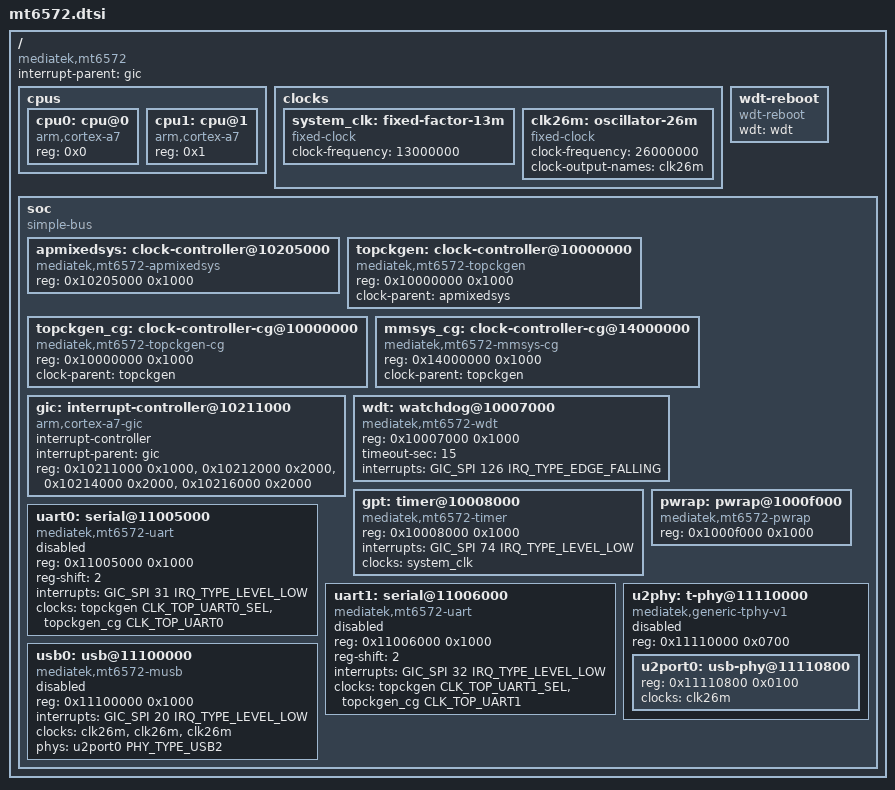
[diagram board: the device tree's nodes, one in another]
#include <dt-bindings/interrupt-controller/irq.h>
#include <dt-bindings/interrupt-controller/arm-gic.h>
#include <dt-bindings/phy/phy.h>

#include <dt-bindings/clock/mt6572-clk.h>

/ {
  compatible = "mediatek,mt6572";
  #address-cells = <1>;
  #size-cells = <1>;
  interrupt-parent = <&gic>;

  cpus {
    #address-cells = <1>;
    #size-cells = <0>;

    cpu0: cpu@0 {
      compatible = "arm,cortex-a7";
      device_type = "cpu";
      reg = <0x0>;
    };

    cpu1: cpu@1 {
      compatible = "arm,cortex-a7";
      device_type = "cpu";
      reg = <0x1>;
    };
  };

  clocks {
    system_clk: fixed-factor-13m {
		  compatible = "fixed-clock";
		  clock-frequency = <13000000>;
		  #clock-cells = <0>;
	  };

    clk26m: oscillator-26m {
      compatible = "fixed-clock";
      #clock-cells = <0>;
      clock-frequency = <26000000>;
      clock-output-names = "clk26m";
    };
  };

  wdt-reboot {
    compatible = "wdt-reboot";
    wdt = <&wdt>;
    status = "okay";
  };

  soc {
    #address-cells = <1>;
    #size-cells = <1>;
    compatible = "simple-bus";
    ranges;

    apmixedsys: clock-controller@10205000 {
      compatible = "mediatek,mt6572-apmixedsys";
      reg = <0x10205000	0x1000>;
      #clock-cells = <1>;
    };

    topckgen: clock-controller@10000000 {
      compatible = "mediatek,mt6572-topckgen";
      reg = <0x10000000 0x1000>;
      clock-parent = <&apmixedsys>;
      #clock-cells = <1>;
    };

    topckgen_cg: clock-controller-cg@10000000 {
      compatible = "mediatek,mt6572-topckgen-cg";
      reg = <0x10000000 0x1000>;
      clock-parent = <&topckgen>;
      #clock-cells = <1>;
    };

    mmsys_cg: clock-controller-cg@14000000 {
      compatible = "mediatek,mt6572-mmsys-cg";
      reg = <0x14000000 0x1000>;
      clock-parent = <&topckgen>;
      #clock-cells = <1>;
    };

    gic: interrupt-controller@10211000 {
      compatible = "arm,cortex-a7-gic";
      interrupt-controller;
      #interrupt-cells = <3>;
      interrupt-parent = <&gic>;
      reg = <0x10211000 0x1000>,
            <0x10212000 0x2000>,
            <0x10214000 0x2000>,
            <0x10216000 0x2000>;
    };

    wdt: watchdog@10007000 {
      compatible = "mediatek,mt6572-wdt";
      reg = <0x10007000 0x1000>;
      timeout-sec = <15>;
      interrupts = <GIC_SPI 126 IRQ_TYPE_EDGE_FALLING>;
    };

    gpt: timer@10008000 {
      compatible = "mediatek,mt6572-timer";
      reg = <0x10008000 0x1000>;
      interrupts = <GIC_SPI 74 IRQ_TYPE_LEVEL_LOW>;
      clocks = <&system_clk>;
      clock-names = "system-clk";
    };

    uart0: serial@11005000 {
      compatible = "mediatek,mt6572-uart";
      reg = <0x11005000 0x1000>;
      reg-shift = <2>;
      interrupts = <GIC_SPI 31 IRQ_TYPE_LEVEL_LOW>;
      clocks =  <&topckgen CLK_TOP_UART0_SEL>,
                <&topckgen_cg CLK_TOP_UART0>;
      clock-names = "baud", "bus";
      status = "disabled";
    };

    uart1: serial@11006000 {
      compatible = "mediatek,mt6572-uart";
      reg = <0x11006000 0x1000>;
      reg-shift = <2>;
      interrupts = <GIC_SPI 32 IRQ_TYPE_LEVEL_LOW>;
      clocks =  <&topckgen CLK_TOP_UART1_SEL>,
                <&topckgen_cg CLK_TOP_UART1>;
      clock-names = "baud", "bus";
      status = "disabled";
    };
    
    pwrap: pwrap@1000f000 {
      compatible = "mediatek,mt6572-pwrap";
      reg = <0x1000f000 0x1000>;
    };

    usb0: usb@11100000 {
		  compatible = "mediatek,mt6572-musb";
		  reg = <0x11100000 0x1000>;
		  reg-names = "control";
      interrupts = <GIC_SPI 20 IRQ_TYPE_LEVEL_LOW>;
		  interrupt-names = "mc";
		  clocks = <&clk26m>, <&clk26m>, <&clk26m>;
      clock-names = "usbpll", "usbmcu", "usb";
      phys = <&u2port0 PHY_TYPE_USB2>;
		  phy-names = "usb";
		  status = "disabled";
	  };

    u2phy: t-phy@11110000 {
		  compatible = "mediatek,generic-tphy-v1";
		  reg = <0x11110000 0x0700>;
      #address-cells = <1>;
		  #size-cells = <1>;
		  ranges;

		  status = "disabled";

		  u2port0: usb-phy@11110800 {
			  reg = <0x11110800 0x0100>;
			  clocks = <&clk26m>;
			  clock-names = "ref";
			  #phy-cells = <1>;
		  };
	  };

    /*    
    pinctrl: pinctrl@10005000 {
      compatible = "mediatek,mt6572-pinctrl";
      reg = <0x10005000 0x1000>, // GPIO
            <0x10208000 0x1000>, // IOCFG_T
            <0x10209000 0x1000>, // IOCFG_B
            <0x1020a000 0x1000>, // IOCFG_L
            <0x1020b000 0x1000>; // IOCFG_R
      reg-names = "gpio", 
                  "iocfg_t",
                  "iocfg_b", 
                  "iocfg_l", 
                  "iocfg_r";

      gpio: gpio-controller {
        gpio-controller;
        #gpio-cells = <2>;
      };
    };
    
    mmc0: mmc@11120000 {
      compatible = "mediatek,mt6572-mmc";
      reg = <0x11120000 0x10000>;
      interrupts = <GIC_SPI 26 IRQ_TYPE_LEVEL_LOW>;
      clocks = <&topckgen_cg CLK_TOP_MSDC0>,
               <&topckgen CLK_TOP_MSDC0_SEL>;
      clock-names = "source", "hclk";
      status = "disabled";
    };

    mmc1: mmc@11130000 {
      compatible = "mediatek,mt6572-mmc";
      reg = <0x11130000 0x10000>;
      interrupts = <GIC_SPI 27 IRQ_TYPE_LEVEL_LOW>;
      clocks = <&topckgen_cg CLK_TOP_MSDC1>,
               <&topckgen CLK_TOP_MSDC1_SEL>;
      clock-names = "source", "hclk";
      status = "disabled";
    };
    */
  };
};
